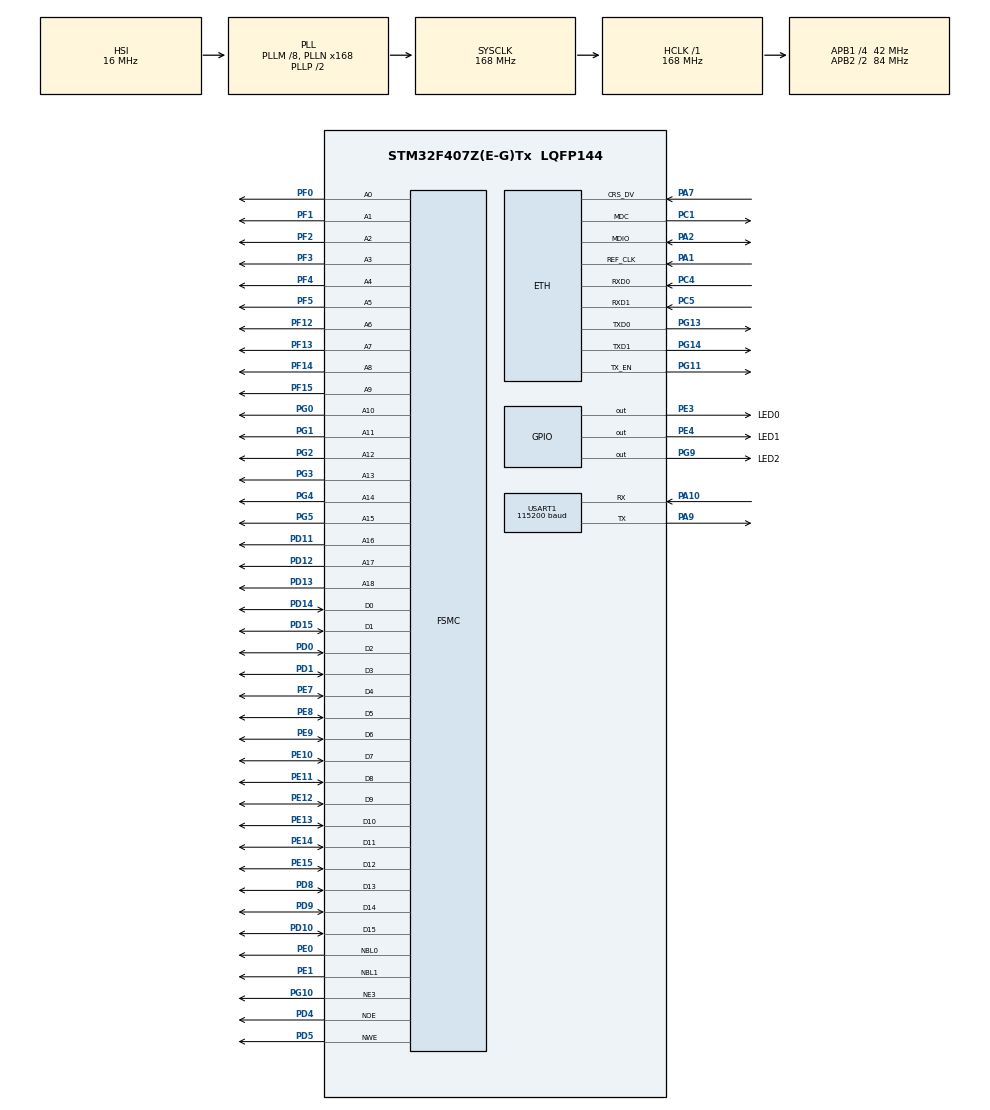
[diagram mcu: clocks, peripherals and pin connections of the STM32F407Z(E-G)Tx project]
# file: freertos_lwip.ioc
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ETH.MediaInterface=ETH_MEDIA_INTERFACE_RMII
FSMC.AddressSetupTime1=10
FSMC.BusTurnAroundDuration1=1
FSMC.DataSetupTime1=6
FSMC.ExtendedMode1=FSMC_EXTENDED_MODE_DISABLE
FSMC.WriteOperation1=FSMC_WRITE_OPERATION_ENABLE
Mcu.Family=STM32F4
Mcu.Name=STM32F407Z(E-G)Tx
Mcu.Package=LQFP144
NVIC.PriorityGroup=NVIC_PRIORITYGROUP_4
PA1.Mode=RMII
PA1.Signal=ETH_REF_CLK
PA10.Mode=Asynchronous
PA10.Signal=USART1_RX
PA13.Mode=Serial_Wire
PA13.Signal=SYS_JTMS-SWDIO
PA14.Mode=Serial_Wire
PA14.Signal=SYS_JTCK-SWCLK
PA2.Mode=RMII
PA2.Signal=ETH_MDIO
PA7.Mode=RMII
PA7.Signal=ETH_CRS_DV
PA9.Mode=Asynchronous
PA9.Signal=USART1_TX
PC1.Mode=RMII
PC1.Signal=ETH_MDC
PC4.Mode=RMII
PC4.Signal=ETH_RXD0
PC5.Mode=RMII
PC5.Signal=ETH_RXD1
PD0.Signal=FSMC_D2_DA2
PD1.Signal=FSMC_D3_DA3
PD10.Signal=FSMC_D15_DA15
PD11.Signal=FSMC_A16_CLE
PD12.Signal=FSMC_A17_ALE
PD13.Signal=FSMC_A18
PD14.Signal=FSMC_D0_DA0
PD15.Signal=FSMC_D1_DA1
PD4.Signal=FSMC_NOE
PD5.Signal=FSMC_NWE
PD8.Signal=FSMC_D13_DA13
PD9.Signal=FSMC_D14_DA14
PE0.Signal=FSMC_NBL0
PE1.Signal=FSMC_NBL1
PE10.Signal=FSMC_D7_DA7
PE11.Signal=FSMC_D8_DA8
PE12.Signal=FSMC_D9_DA9
PE13.Signal=FSMC_D10_DA10
PE14.Signal=FSMC_D11_DA11
PE15.Signal=FSMC_D12_DA12
PE3.GPIO_Label=LED0
PE3.GPIO_Speed=GPIO_SPEED_FREQ_HIGH
PE3.Signal=GPIO_Output
PE4.GPIO_Label=LED1
PE4.GPIO_Speed=GPIO_SPEED_FREQ_HIGH
PE4.Signal=GPIO_Output
PE6.Signal=S_TIM9_CH2
PE7.Signal=FSMC_D4_DA4
PE8.Signal=FSMC_D5_DA5
PE9.Signal=FSMC_D6_DA6
PF0.Signal=FSMC_A0
PF1.Signal=FSMC_A1
PF12.Signal=FSMC_A6
PF13.Signal=FSMC_A7
PF14.Signal=FSMC_A8
PF15.Signal=FSMC_A9
PF2.Signal=FSMC_A2
PF3.Signal=FSMC_A3
PF4.Signal=FSMC_A4
PF5.Signal=FSMC_A5
PG0.Signal=FSMC_A10
PG1.Signal=FSMC_A11
PG10.Mode=NorPsramChipSelect3_1
PG10.Signal=FSMC_NE3
PG11.Mode=RMII
PG11.Signal=ETH_TX_EN
PG13.Mode=RMII
PG13.Signal=ETH_TXD0
PG14.Mode=RMII
PG14.Signal=ETH_TXD1
PG2.Signal=FSMC_A12
PG3.Signal=FSMC_A13
PG4.Signal=FSMC_A14
PG5.Signal=FSMC_A15
PG9.GPIO_Label=LED2
PG9.GPIO_Speed=GPIO_SPEED_FREQ_HIGH
PG9.Signal=GPIO_Output
PH0-OSC_IN.Mode=HSE-External-Oscillator
PH0-OSC_IN.Signal=RCC_OSC_IN
PH1-OSC_OUT.Mode=HSE-External-Oscillator
PH1-OSC_OUT.Signal=RCC_OSC_OUT
ProjectManager.HeapSize=0x200
ProjectManager.StackSize=0x400
ProjectManager.TargetToolchain=TrueSTUDIO
RCC.48MHZClocksFreq_Value=84000000
RCC.AHBFreq_Value=168000000
RCC.APB1CLKDivider=RCC_HCLK_DIV4
RCC.APB1Freq_Value=42000000
RCC.APB1TimFreq_Value=84000000
RCC.APB2CLKDivider=RCC_HCLK_DIV2
RCC.APB2Freq_Value=84000000
RCC.APB2TimFreq_Value=168000000
RCC.CortexFreq_Value=168000000
RCC.HCLKFreq_Value=168000000
RCC.HSE_VALUE=8000000
RCC.HSI_VALUE=16000000
RCC.LSE_VALUE=32768
RCC.PLLM=8
RCC.PLLN=168
RCC.SYSCLKFreq_VALUE=168000000
RCC.SYSCLKSource=RCC_SYSCLKSOURCE_PLLCLK
RCC.VCOOutputFreq_Value=336000000
SH.FSMC_A0.0=FSMC_A0,19b-a1
SH.FSMC_A1.0=FSMC_A1,19b-a1
SH.FSMC_A10.0=FSMC_A10,19b-a1
SH.FSMC_A11.0=FSMC_A11,19b-a1
SH.FSMC_A12.0=FSMC_A12,19b-a1
SH.FSMC_A13.0=FSMC_A13,19b-a1
SH.FSMC_A14.0=FSMC_A14,19b-a1
SH.FSMC_A15.0=FSMC_A15,19b-a1
SH.FSMC_A16_CLE.0=FSMC_A16,19b-a1
SH.FSMC_A17_ALE.0=FSMC_A17,19b-a1
SH.FSMC_A18.0=FSMC_A18,19b-a1
SH.FSMC_A2.0=FSMC_A2,19b-a1
SH.FSMC_A3.0=FSMC_A3,19b-a1
SH.FSMC_A4.0=FSMC_A4,19b-a1
SH.FSMC_A5.0=FSMC_A5,19b-a1
SH.FSMC_A6.0=FSMC_A6,19b-a1
SH.FSMC_A7.0=FSMC_A7,19b-a1
SH.FSMC_A8.0=FSMC_A8,19b-a1
SH.FSMC_A9.0=FSMC_A9,19b-a1
SH.FSMC_D0_DA0.0=FSMC_D0,16b-d1
SH.FSMC_D10_DA10.0=FSMC_D10,16b-d1
SH.FSMC_D11_DA11.0=FSMC_D11,16b-d1
SH.FSMC_D12_DA12.0=FSMC_D12,16b-d1
SH.FSMC_D13_DA13.0=FSMC_D13,16b-d1
SH.FSMC_D14_DA14.0=FSMC_D14,16b-d1
SH.FSMC_D15_DA15.0=FSMC_D15,16b-d1
SH.FSMC_D1_DA1.0=FSMC_D1,16b-d1
SH.FSMC_D2_DA2.0=FSMC_D2,16b-d1
SH.FSMC_D3_DA3.0=FSMC_D3,16b-d1
SH.FSMC_D4_DA4.0=FSMC_D4,16b-d1
SH.FSMC_D5_DA5.0=FSMC_D5,16b-d1
SH.FSMC_D6_DA6.0=FSMC_D6,16b-d1
SH.FSMC_D7_DA7.0=FSMC_D7,16b-d1
SH.FSMC_D8_DA8.0=FSMC_D8,16b-d1
SH.FSMC_D9_DA9.0=FSMC_D9,16b-d1
SH.FSMC_NBL0.0=FSMC_NBL0,2ByteEnable1
SH.FSMC_NBL1.0=FSMC_NBL1,2ByteEnable1
SH.FSMC_NOE.0=FSMC_NOE,Sram1
SH.FSMC_NWE.0=FSMC_NWE,Sram1
SH.S_TIM9_CH2.0=TIM9_CH2
USART1.BaudRate=115200
USART1.VirtualMode=VM_ASYNC
board=custom

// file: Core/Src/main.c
/**
  ******************************************************************************
  * @file           : main.c
  * @brief          : Main program body
  ******************************************************************************
  ** This notice applies to any and all portions of this file
  * that are not between comment pairs USER CODE BEGIN and
  * USER CODE END. Other portions of this file, whether
  * inserted by the user or by software development tools
  * are owned by their respective copyright owners.
  *
  * COPYRIGHT(c) 2018 STMicroelectronics
  *
  * Redistribution and use in source and binary forms, with or without modification,
  * are permitted provided that the following conditions are met:
  *   1. Redistributions of source code must retain the above copyright notice,
  *      this list of conditions and the following disclaimer.
  *   2. Redistributions in binary form must reproduce the above copyright notice,
  *      this list of conditions and the following disclaimer in the documentation
  *      and/or other materials provided with the distribution.
  *   3. Neither the name of STMicroelectronics nor the names of its contributors
  *      may be used to endorse or promote products derived from this software
  *      without specific prior written permission.
  *
  * THIS SOFTWARE IS PROVIDED BY THE COPYRIGHT HOLDERS AND CONTRIBUTORS "AS IS"
  * AND ANY EXPRESS OR IMPLIED WARRANTIES, INCLUDING, BUT NOT LIMITED TO, THE
  * IMPLIED WARRANTIES OF MERCHANTABILITY AND FITNESS FOR A PARTICULAR PURPOSE ARE
  * DISCLAIMED. IN NO EVENT SHALL THE COPYRIGHT HOLDER OR CONTRIBUTORS BE LIABLE
  * FOR ANY DIRECT, INDIRECT, INCIDENTAL, SPECIAL, EXEMPLARY, OR CONSEQUENTIAL
  * DAMAGES (INCLUDING, BUT NOT LIMITED TO, PROCUREMENT OF SUBSTITUTE GOODS OR
  * SERVICES; LOSS OF USE, DATA, OR PROFITS; OR BUSINESS INTERRUPTION) HOWEVER
  * CAUSED AND ON ANY THEORY OF LIABILITY, WHETHER IN CONTRACT, STRICT LIABILITY,
  * OR TORT (INCLUDING NEGLIGENCE OR OTHERWISE) ARISING IN ANY WAY OUT OF THE USE
  * OF THIS SOFTWARE, EVEN IF ADVISED OF THE POSSIBILITY OF SUCH DAMAGE.
  *
  ******************************************************************************
  */
#include "main.h"
#include "stm32f4xx_hal.h"

/* USER CODE BEGIN Includes */
#include "sram.h"
/* USER CODE END Includes */

UART_HandleTypeDef huart1;

SRAM_HandleTypeDef hsram1;

/* USER CODE BEGIN PV */
/* Private variables ---------------------------------------------------------*/

/* USER CODE END PV */

void SystemClock_Config(void);
static void MX_GPIO_Init(void);
static void MX_FSMC_Init(void);
static void MX_USART1_UART_Init(void);

/* USER CODE BEGIN PFP */
/* Private function prototypes -----------------------------------------------*/

/* USER CODE END PFP */

int main(void)
{

  /* MCU Configuration----------------------------------------------------------*/

  /* Reset of all peripherals, Initializes the Flash interface and the Systick. */
  HAL_Init();

  /* Configure the system clock */
  SystemClock_Config();

  /* Initialize all configured peripherals */
  MX_GPIO_Init();
  MX_FSMC_Init();
  MX_USART1_UART_Init();

  /* Infinite loop */
  while (1)
  {

  /* USER CODE BEGIN 3 */
	HAL_GPIO_TogglePin(LED0_GPIO_Port, LED0_Pin);
	HAL_Delay(100);
	HAL_GPIO_TogglePin(LED1_GPIO_Port, LED1_Pin);
	HAL_Delay(100);
	HAL_GPIO_TogglePin(LED2_GPIO_Port, LED2_Pin);
	HAL_Delay(100);

	sram_test();
  }
  /* USER CODE END 3 */

}

void SystemClock_Config(void)
{

  RCC_OscInitTypeDef RCC_OscInitStruct;
  RCC_ClkInitTypeDef RCC_ClkInitStruct;

    /**Configure the main internal regulator output voltage
    */
  __HAL_RCC_PWR_CLK_ENABLE();

  __HAL_PWR_VOLTAGESCALING_CONFIG(PWR_REGULATOR_VOLTAGE_SCALE1);

    /**Initializes the CPU, AHB and APB busses clocks
    */
  RCC_OscInitStruct.OscillatorType = RCC_OSCILLATORTYPE_HSI;
  RCC_OscInitStruct.HSIState = RCC_HSI_ON;
  RCC_OscInitStruct.HSICalibrationValue = 16;
  RCC_OscInitStruct.PLL.PLLState = RCC_PLL_ON;
  RCC_OscInitStruct.PLL.PLLSource = RCC_PLLSOURCE_HSI;
  RCC_OscInitStruct.PLL.PLLM = 8;
  RCC_OscInitStruct.PLL.PLLN = 168;
  RCC_OscInitStruct.PLL.PLLP = RCC_PLLP_DIV2;
  RCC_OscInitStruct.PLL.PLLQ = 4;
  if (HAL_RCC_OscConfig(&RCC_OscInitStruct) != HAL_OK)
  {
    _Error_Handler(__FILE__, __LINE__);
  }

    /**Initializes the CPU, AHB and APB busses clocks
    */
  RCC_ClkInitStruct.ClockType = RCC_CLOCKTYPE_HCLK|RCC_CLOCKTYPE_SYSCLK
                              |RCC_CLOCKTYPE_PCLK1|RCC_CLOCKTYPE_PCLK2;
  RCC_ClkInitStruct.SYSCLKSource = RCC_SYSCLKSOURCE_PLLCLK;
  RCC_ClkInitStruct.AHBCLKDivider = RCC_SYSCLK_DIV1;
  RCC_ClkInitStruct.APB1CLKDivider = RCC_HCLK_DIV4;
  RCC_ClkInitStruct.APB2CLKDivider = RCC_HCLK_DIV2;

  if (HAL_RCC_ClockConfig(&RCC_ClkInitStruct, FLASH_LATENCY_5) != HAL_OK)
  {
    _Error_Handler(__FILE__, __LINE__);
  }

    /**Configure the Systick interrupt time
    */
  HAL_SYSTICK_Config(HAL_RCC_GetHCLKFreq()/1000);

    /**Configure the Systick
    */
  HAL_SYSTICK_CLKSourceConfig(SYSTICK_CLKSOURCE_HCLK);

  /* SysTick_IRQn interrupt configuration */
  HAL_NVIC_SetPriority(SysTick_IRQn, 0, 0);
}

/* USART1 init function */
static void MX_USART1_UART_Init(void)
{

  huart1.Instance = USART1;
  huart1.Init.BaudRate = 115200;
  huart1.Init.WordLength = UART_WORDLENGTH_8B;
  huart1.Init.StopBits = UART_STOPBITS_1;
  huart1.Init.Parity = UART_PARITY_NONE;
  huart1.Init.Mode = UART_MODE_TX_RX;
  huart1.Init.HwFlowCtl = UART_HWCONTROL_NONE;
  huart1.Init.OverSampling = UART_OVERSAMPLING_16;
  if (HAL_UART_Init(&huart1) != HAL_OK)
  {
    _Error_Handler(__FILE__, __LINE__);
  }

}

/** Configure pins as
        * Analog
        * Input
        * Output
        * EVENT_OUT
        * EXTI
     PE6   ------> S_TIM9_CH2
*/
static void MX_GPIO_Init(void)
{

  GPIO_InitTypeDef GPIO_InitStruct;

  /* GPIO Ports Clock Enable */
  __HAL_RCC_GPIOE_CLK_ENABLE();
  __HAL_RCC_GPIOF_CLK_ENABLE();
  __HAL_RCC_GPIOH_CLK_ENABLE();
  __HAL_RCC_GPIOG_CLK_ENABLE();
  __HAL_RCC_GPIOD_CLK_ENABLE();
  __HAL_RCC_GPIOA_CLK_ENABLE();

  /*Configure GPIO pin Output Level */
  HAL_GPIO_WritePin(GPIOE, LED0_Pin|LED1_Pin, GPIO_PIN_RESET);

  /*Configure GPIO pin Output Level */
  HAL_GPIO_WritePin(LED2_GPIO_Port, LED2_Pin, GPIO_PIN_RESET);

  /*Configure GPIO pins : LED0_Pin LED1_Pin */
  GPIO_InitStruct.Pin = LED0_Pin|LED1_Pin;
  GPIO_InitStruct.Mode = GPIO_MODE_OUTPUT_PP;
  GPIO_InitStruct.Pull = GPIO_NOPULL;
  GPIO_InitStruct.Speed = GPIO_SPEED_FREQ_HIGH;
  HAL_GPIO_Init(GPIOE, &GPIO_InitStruct);

  /*Configure GPIO pin : PE6 */
  GPIO_InitStruct.Pin = GPIO_PIN_6;
  GPIO_InitStruct.Mode = GPIO_MODE_AF_PP;
  GPIO_InitStruct.Pull = GPIO_NOPULL;
  GPIO_InitStruct.Speed = GPIO_SPEED_FREQ_LOW;
  GPIO_InitStruct.Alternate = GPIO_AF3_TIM9;
  HAL_GPIO_Init(GPIOE, &GPIO_InitStruct);

  /*Configure GPIO pin : LED2_Pin */
  GPIO_InitStruct.Pin = LED2_Pin;
  GPIO_InitStruct.Mode = GPIO_MODE_OUTPUT_PP;
  GPIO_InitStruct.Pull = GPIO_NOPULL;
  GPIO_InitStruct.Speed = GPIO_SPEED_FREQ_HIGH;
  HAL_GPIO_Init(LED2_GPIO_Port, &GPIO_InitStruct);

}

/* FSMC initialization function */
static void MX_FSMC_Init(void)
{
  FSMC_NORSRAM_TimingTypeDef Timing;

  /** Perform the SRAM1 memory initialization sequence
  */
  hsram1.Instance = FSMC_NORSRAM_DEVICE;
  hsram1.Extended = FSMC_NORSRAM_EXTENDED_DEVICE;
  /* hsram1.Init */
  hsram1.Init.NSBank = FSMC_NORSRAM_BANK3;
  hsram1.Init.DataAddressMux = FSMC_DATA_ADDRESS_MUX_DISABLE;
  hsram1.Init.MemoryType = FSMC_MEMORY_TYPE_SRAM;
  hsram1.Init.MemoryDataWidth = FSMC_NORSRAM_MEM_BUS_WIDTH_16;
  hsram1.Init.BurstAccessMode = FSMC_BURST_ACCESS_MODE_DISABLE;
  hsram1.Init.WaitSignalPolarity = FSMC_WAIT_SIGNAL_POLARITY_LOW;
  hsram1.Init.WrapMode = FSMC_WRAP_MODE_DISABLE;
  hsram1.Init.WaitSignalActive = FSMC_WAIT_TIMING_BEFORE_WS;
  hsram1.Init.WriteOperation = FSMC_WRITE_OPERATION_ENABLE;
  hsram1.Init.WaitSignal = FSMC_WAIT_SIGNAL_DISABLE;
  hsram1.Init.ExtendedMode = FSMC_EXTENDED_MODE_DISABLE;
  hsram1.Init.AsynchronousWait = FSMC_ASYNCHRONOUS_WAIT_DISABLE;
  hsram1.Init.WriteBurst = FSMC_WRITE_BURST_DISABLE;
  hsram1.Init.PageSize = FSMC_PAGE_SIZE_NONE;
  /* Timing */
  Timing.AddressSetupTime = 10;
  Timing.AddressHoldTime = 15;
  Timing.DataSetupTime = 6;
  Timing.BusTurnAroundDuration = 1;
  Timing.CLKDivision = 16;
  Timing.DataLatency = 17;
  Timing.AccessMode = FSMC_ACCESS_MODE_A;
  /* ExtTiming */

  if (HAL_SRAM_Init(&hsram1, &Timing, NULL) != HAL_OK)
  {
    _Error_Handler(__FILE__, __LINE__);
  }

}

void _Error_Handler(char *file, int line)
{
  while(1)
  {
  }
}

/************************ (C) COPYRIGHT STMicroelectronics *****END OF FILE****/
